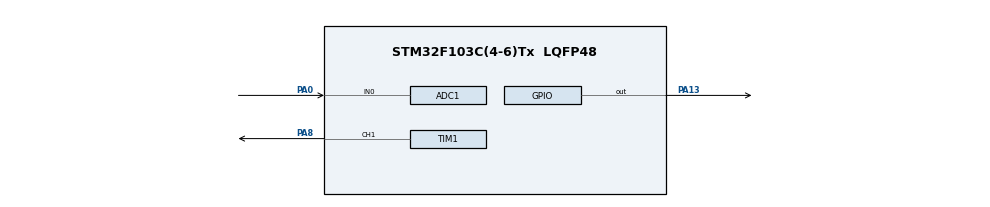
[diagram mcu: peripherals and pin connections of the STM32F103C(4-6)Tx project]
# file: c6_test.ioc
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ADC1.Channel-0\#ChannelRegularConversion=ADC_CHANNEL_0
ADC1.DataAlign=ADC_DATAALIGN_LEFT
ADC1.NbrOfConversion=1
ADC1.NbrOfConversionFlag=1
ADC1.Rank-0\#ChannelRegularConversion=1
ADC1.SamplingTime-0\#ChannelRegularConversion=ADC_SAMPLETIME_1CYCLE_5
ADC1.master=1
Mcu.Family=STM32F1
Mcu.Name=STM32F103C(4-6)Tx
Mcu.Package=LQFP48
NVIC.ADC1_2_IRQn=true\:0\:0\:false\:false\:true\:true\:true
NVIC.PriorityGroup=NVIC_PRIORITYGROUP_4
NVIC.TIM1_CC_IRQn=true\:0\:0\:false\:false\:true\:true\:true
PA0-WKUP.Signal=ADCx_IN0
PA13.PinState=GPIO_PIN_SET
PA13.Signal=GPIO_Output
PA8.Signal=S_TIM1_CH1
ProjectManager.HeapSize=0x200
ProjectManager.StackSize=0x400
ProjectManager.TargetToolchain=Makefile
RCC.APB1Freq_Value=8000000
RCC.APB2Freq_Value=8000000
SH.ADCx_IN0.0=ADC1_IN0,IN0
SH.S_TIM1_CH1.0=TIM1_CH1,Output Compare1 CH1
TIM1.Channel-Output\ Compare1\ CH1=TIM_CHANNEL_1
TIM1.Period=30000
TIM1.Prescaler=1000
TIM1.Pulse-Output\ Compare1\ CH1=10000
VP_SYS_VS_ND.Mode=No_Debug
VP_TIM1_VS_ClockSourceINT.Mode=Internal
board=custom

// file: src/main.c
/* USER CODE BEGIN Header */
/**
  ******************************************************************************
  * @file           : main.c
  * @brief          : Main program body
  ******************************************************************************
  * @attention
  *
  * <h2><center>&copy; Copyright (c) 2021 STMicroelectronics.
  * All rights reserved.</center></h2>
  *
  * This software component is licensed by ST under BSD 3-Clause license,
  * the "License"; You may not use this file except in compliance with the
  * License. You may obtain a copy of the License at:
  *                        opensource.org/licenses/BSD-3-Clause
  *
  ******************************************************************************
  */
/* USER CODE END Header */
#include "main.h"

ADC_HandleTypeDef hadc1;

TIM_HandleTypeDef htim1;

/* USER CODE BEGIN PV */
uint32_t value_adc;

/* USER CODE END PV */

void SystemClock_Config(void);
static void MX_GPIO_Init(void);
static void MX_TIM1_Init(void);
static void MX_ADC1_Init(void);

int main(void)
{

  /* MCU Configuration--------------------------------------------------------*/

  /* Reset of all peripherals, Initializes the Flash interface and the Systick. */
  HAL_Init();

  /* Configure the system clock */
  SystemClock_Config();

  /* Initialize all configured peripherals */
  MX_GPIO_Init();
  MX_TIM1_Init();
  MX_ADC1_Init();
  /* USER CODE BEGIN 2 */
  HAL_ADC_Start_IT(&hadc1);
  /* USER CODE END 2 */

  /* Infinite loop */
  /* USER CODE BEGIN WHILE */
  while (1)
  {
    HAL_GPIO_TogglePin(GPIOA, GPIO_PIN_13);
    HAL_Delay(100);
    HAL_ADC_Start_IT(&hadc1);
    /* USER CODE END WHILE */

  }
}

void SystemClock_Config(void)
{
  RCC_OscInitTypeDef RCC_OscInitStruct = {0};
  RCC_ClkInitTypeDef RCC_ClkInitStruct = {0};
  RCC_PeriphCLKInitTypeDef PeriphClkInit = {0};

  /** Initializes the RCC Oscillators according to the specified parameters
  * in the RCC_OscInitTypeDef structure.
  */
  RCC_OscInitStruct.OscillatorType = RCC_OSCILLATORTYPE_HSI;
  RCC_OscInitStruct.HSIState = RCC_HSI_ON;
  RCC_OscInitStruct.HSICalibrationValue = RCC_HSICALIBRATION_DEFAULT;
  RCC_OscInitStruct.PLL.PLLState = RCC_PLL_NONE;
  if (HAL_RCC_OscConfig(&RCC_OscInitStruct) != HAL_OK)
  {
    Error_Handler();
  }
  /** Initializes the CPU, AHB and APB buses clocks
  */
  RCC_ClkInitStruct.ClockType = RCC_CLOCKTYPE_HCLK|RCC_CLOCKTYPE_SYSCLK
                              |RCC_CLOCKTYPE_PCLK1|RCC_CLOCKTYPE_PCLK2;
  RCC_ClkInitStruct.SYSCLKSource = RCC_SYSCLKSOURCE_HSI;
  RCC_ClkInitStruct.AHBCLKDivider = RCC_SYSCLK_DIV1;
  RCC_ClkInitStruct.APB1CLKDivider = RCC_HCLK_DIV1;
  RCC_ClkInitStruct.APB2CLKDivider = RCC_HCLK_DIV1;

  if (HAL_RCC_ClockConfig(&RCC_ClkInitStruct, FLASH_LATENCY_0) != HAL_OK)
  {
    Error_Handler();
  }
  PeriphClkInit.PeriphClockSelection = RCC_PERIPHCLK_ADC;
  PeriphClkInit.AdcClockSelection = RCC_ADCPCLK2_DIV2;
  if (HAL_RCCEx_PeriphCLKConfig(&PeriphClkInit) != HAL_OK)
  {
    Error_Handler();
  }
}

static void MX_ADC1_Init(void)
{

  ADC_ChannelConfTypeDef sConfig = {0};

  /** Common config
  */
  hadc1.Instance = ADC1;
  hadc1.Init.ScanConvMode = ADC_SCAN_DISABLE;
  hadc1.Init.ContinuousConvMode = DISABLE;
  hadc1.Init.DiscontinuousConvMode = DISABLE;
  hadc1.Init.ExternalTrigConv = ADC_SOFTWARE_START;
  hadc1.Init.DataAlign = ADC_DATAALIGN_LEFT;
  hadc1.Init.NbrOfConversion = 1;
  if (HAL_ADC_Init(&hadc1) != HAL_OK)
  {
    Error_Handler();
  }
  /** Configure Regular Channel
  */
  sConfig.Channel = ADC_CHANNEL_0;
  sConfig.Rank = ADC_REGULAR_RANK_1;
  sConfig.SamplingTime = ADC_SAMPLETIME_1CYCLE_5;
  if (HAL_ADC_ConfigChannel(&hadc1, &sConfig) != HAL_OK)
  {
    Error_Handler();
  }

}

static void MX_TIM1_Init(void)
{

  TIM_ClockConfigTypeDef sClockSourceConfig = {0};
  TIM_MasterConfigTypeDef sMasterConfig = {0};
  TIM_OC_InitTypeDef sConfigOC = {0};
  TIM_BreakDeadTimeConfigTypeDef sBreakDeadTimeConfig = {0};

  htim1.Instance = TIM1;
  htim1.Init.Prescaler = 1000;
  htim1.Init.CounterMode = TIM_COUNTERMODE_UP;
  htim1.Init.Period = 30000;
  htim1.Init.ClockDivision = TIM_CLOCKDIVISION_DIV1;
  htim1.Init.RepetitionCounter = 0;
  htim1.Init.AutoReloadPreload = TIM_AUTORELOAD_PRELOAD_DISABLE;
  if (HAL_TIM_Base_Init(&htim1) != HAL_OK)
  {
    Error_Handler();
  }
  sClockSourceConfig.ClockSource = TIM_CLOCKSOURCE_INTERNAL;
  if (HAL_TIM_ConfigClockSource(&htim1, &sClockSourceConfig) != HAL_OK)
  {
    Error_Handler();
  }
  if (HAL_TIM_OC_Init(&htim1) != HAL_OK)
  {
    Error_Handler();
  }
  sMasterConfig.MasterOutputTrigger = TIM_TRGO_RESET;
  sMasterConfig.MasterSlaveMode = TIM_MASTERSLAVEMODE_DISABLE;
  if (HAL_TIMEx_MasterConfigSynchronization(&htim1, &sMasterConfig) != HAL_OK)
  {
    Error_Handler();
  }
  sConfigOC.OCMode = TIM_OCMODE_TIMING;
  sConfigOC.Pulse = 10000;
  sConfigOC.OCPolarity = TIM_OCPOLARITY_HIGH;
  sConfigOC.OCNPolarity = TIM_OCNPOLARITY_HIGH;
  sConfigOC.OCFastMode = TIM_OCFAST_DISABLE;
  sConfigOC.OCIdleState = TIM_OCIDLESTATE_RESET;
  sConfigOC.OCNIdleState = TIM_OCNIDLESTATE_RESET;
  if (HAL_TIM_OC_ConfigChannel(&htim1, &sConfigOC, TIM_CHANNEL_1) != HAL_OK)
  {
    Error_Handler();
  }
  sBreakDeadTimeConfig.OffStateRunMode = TIM_OSSR_DISABLE;
  sBreakDeadTimeConfig.OffStateIDLEMode = TIM_OSSI_DISABLE;
  sBreakDeadTimeConfig.LockLevel = TIM_LOCKLEVEL_OFF;
  sBreakDeadTimeConfig.DeadTime = 0;
  sBreakDeadTimeConfig.BreakState = TIM_BREAK_DISABLE;
  sBreakDeadTimeConfig.BreakPolarity = TIM_BREAKPOLARITY_HIGH;
  sBreakDeadTimeConfig.AutomaticOutput = TIM_AUTOMATICOUTPUT_DISABLE;
  if (HAL_TIMEx_ConfigBreakDeadTime(&htim1, &sBreakDeadTimeConfig) != HAL_OK)
  {
    Error_Handler();
  }
  HAL_TIM_MspPostInit(&htim1);

}

static void MX_GPIO_Init(void)
{
  GPIO_InitTypeDef GPIO_InitStruct = {0};

  /* GPIO Ports Clock Enable */
  __HAL_RCC_GPIOA_CLK_ENABLE();

  /*Configure GPIO pin Output Level */
  HAL_GPIO_WritePin(GPIOA, GPIO_PIN_13, GPIO_PIN_SET);

  /*Configure GPIO pin : PA13 */
  GPIO_InitStruct.Pin = GPIO_PIN_13;
  GPIO_InitStruct.Mode = GPIO_MODE_OUTPUT_PP;
  GPIO_InitStruct.Pull = GPIO_NOPULL;
  GPIO_InitStruct.Speed = GPIO_SPEED_FREQ_LOW;
  HAL_GPIO_Init(GPIOA, &GPIO_InitStruct);

}

/* USER CODE BEGIN 4 */
void HAL_ADC_ConvCpltCallback(ADC_HandleTypeDef* hadc){
  value_adc = HAL_ADC_GetValue(hadc);
}
/* USER CODE END 4 */

void Error_Handler(void)
{
  __disable_irq();
  while (1)
  {
  }
}

/************************ (C) COPYRIGHT STMicroelectronics *****END OF FILE****/
